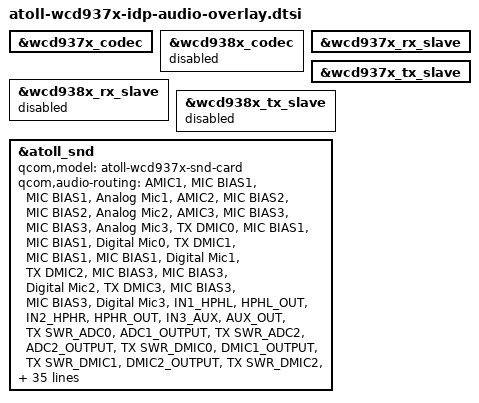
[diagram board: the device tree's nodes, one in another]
/*
 * Copyright (c) 2019, The Linux Foundation. All rights reserved.
 *
 * This program is free software; you can redistribute it and/or modify
 * it under the terms of the GNU General Public License version 2 and
 * only version 2 as published by the Free Software Foundation.
 *
 * This program is distributed in the hope that it will be useful,
 * but WITHOUT ANY WARRANTY; without even the implied warranty of
 * MERCHANTABILITY or FITNESS FOR A PARTICULAR PURPOSE.  See the
 * GNU General Public License for more details.
 */

#include "atoll-audio-overlay.dtsi"

&wcd937x_codec {
	status = "ok";
};

&wcd938x_codec {
	status = "disabled";
};

&wcd937x_rx_slave {
	status = "ok";
};

&wcd937x_tx_slave {
	status = "ok";
};

&wcd938x_rx_slave {
	status = "disabled";
};

&wcd938x_tx_slave {
	status = "disabled";
};


&atoll_snd {
	qcom,model = "atoll-wcd937x-snd-card";
	qcom,audio-routing =
		"AMIC1", "MIC BIAS1",
		"MIC BIAS1", "Analog Mic1",
		"AMIC2", "MIC BIAS2",
		"MIC BIAS2", "Analog Mic2",
		"AMIC3", "MIC BIAS3",
		"MIC BIAS3", "Analog Mic3",
		"TX DMIC0", "MIC BIAS1",
		"MIC BIAS1", "Digital Mic0",
		"TX DMIC1", "MIC BIAS1",
		"MIC BIAS1", "Digital Mic1",
		"TX DMIC2", "MIC BIAS3",
		"MIC BIAS3", "Digital Mic2",
		"TX DMIC3", "MIC BIAS3",
		"MIC BIAS3", "Digital Mic3",
		"IN1_HPHL", "HPHL_OUT",
		"IN2_HPHR", "HPHR_OUT",
		"IN3_AUX", "AUX_OUT",
		"TX SWR_ADC0", "ADC1_OUTPUT",
		"TX SWR_ADC2", "ADC2_OUTPUT",
		"TX SWR_DMIC0", "DMIC1_OUTPUT",
		"TX SWR_DMIC1", "DMIC2_OUTPUT",
		"TX SWR_DMIC2", "DMIC3_OUTPUT",
		"TX SWR_DMIC3", "DMIC4_OUTPUT",
		"TX SWR_DMIC4", "DMIC5_OUTPUT",
		"TX SWR_DMIC5", "DMIC6_OUTPUT",
		"TX SWR_DMIC6", "DMIC7_OUTPUT",
		"TX SWR_DMIC7", "DMIC8_OUTPUT",
		"WSA SRC0_INP", "SRC0",
		"WSA_TX DEC0_INP", "TX DEC0 MUX",
		"WSA_TX DEC1_INP", "TX DEC1 MUX",
		"RX_TX DEC0_INP", "TX DEC0 MUX",
		"RX_TX DEC1_INP", "TX DEC1 MUX",
		"RX_TX DEC2_INP", "TX DEC2 MUX",
		"RX_TX DEC3_INP", "TX DEC3 MUX",
		"SpkrLeft IN", "WSA_SPK1 OUT",
		"SpkrRight IN", "WSA_SPK2 OUT",
		"VA_AIF1 CAP", "VA_SWR_CLK",
		"VA_AIF2 CAP", "VA_SWR_CLK",
		"VA_AIF3 CAP", "VA_SWR_CLK",
		"VA MIC BIAS1", "Digital Mic0",
		"VA MIC BIAS1", "Digital Mic1",
		"VA MIC BIAS3", "Digital Mic2",
		"VA MIC BIAS3", "Digital Mic3",
		"VA DMIC0", "VA MIC BIAS1",
		"VA DMIC1", "VA MIC BIAS1",
		"VA DMIC2", "VA MIC BIAS3",
		"VA DMIC3", "VA MIC BIAS3",
		"VA SWR_ADC0", "VA_SWR_CLK",
		"VA SWR_ADC1", "VA_SWR_CLK",
		"VA SWR_ADC2", "VA_SWR_CLK",
		"VA SWR_ADC3", "VA_SWR_CLK",
		"VA SWR_MIC0", "VA_SWR_CLK",
		"VA SWR_MIC1", "VA_SWR_CLK",
		"VA SWR_MIC2", "VA_SWR_CLK",
		"VA SWR_MIC3", "VA_SWR_CLK",
		"VA SWR_MIC4", "VA_SWR_CLK",
		"VA SWR_MIC5", "VA_SWR_CLK",
		"VA SWR_MIC6", "VA_SWR_CLK",
		"VA SWR_MIC7", "VA_SWR_CLK",
		"VA SWR_ADC0", "ADC1_OUTPUT",
		"VA SWR_ADC1", "ADC2_OUTPUT",
		"VA SWR_ADC2", "ADC3_OUTPUT",
		"VA SWR_ADC3", "ADC4_OUTPUT",
		"VA SWR_MIC0", "DMIC1_OUTPUT",
		"VA SWR_MIC1", "DMIC2_OUTPUT",
		"VA SWR_MIC2", "DMIC3_OUTPUT",
		"VA SWR_MIC3", "DMIC4_OUTPUT",
		"VA SWR_MIC4", "DMIC5_OUTPUT",
		"VA SWR_MIC5", "DMIC6_OUTPUT",
		"VA SWR_MIC6", "DMIC7_OUTPUT",
		"VA SWR_MIC7", "DMIC8_OUTPUT";
	qcom,codec-aux-devs = <&wcd937x_codec>;
};

